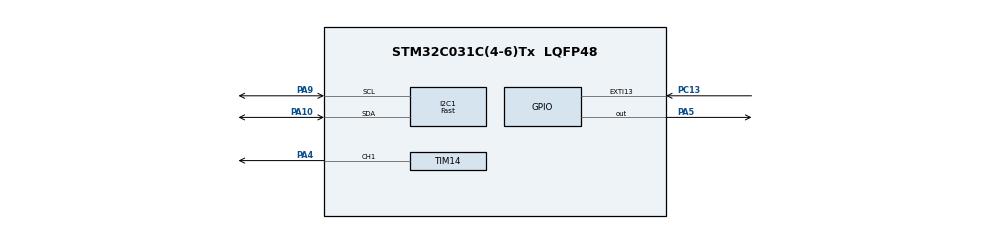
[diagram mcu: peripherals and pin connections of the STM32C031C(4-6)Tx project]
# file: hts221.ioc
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Dma.I2C1_RX.1.Direction=DMA_PERIPH_TO_MEMORY
Dma.I2C1_RX.1.EventEnable=DISABLE
Dma.I2C1_RX.1.Instance=DMA1_Channel2
Dma.I2C1_RX.1.MemDataAlignment=DMA_MDATAALIGN_BYTE
Dma.I2C1_RX.1.MemInc=DMA_MINC_ENABLE
Dma.I2C1_RX.1.Mode=DMA_NORMAL
Dma.I2C1_RX.1.PeriphDataAlignment=DMA_PDATAALIGN_BYTE
Dma.I2C1_RX.1.PeriphInc=DMA_PINC_DISABLE
Dma.I2C1_RX.1.Polarity=HAL_DMAMUX_REQ_GEN_RISING
Dma.I2C1_RX.1.Priority=DMA_PRIORITY_LOW
Dma.I2C1_RX.1.RequestNumber=1
Dma.I2C1_RX.1.SignalID=NONE
Dma.I2C1_RX.1.SyncEnable=DISABLE
Dma.I2C1_RX.1.SyncPolarity=HAL_DMAMUX_SYNC_NO_EVENT
Dma.I2C1_RX.1.SyncRequestNumber=1
Dma.I2C1_RX.1.SyncSignalID=NONE
Dma.I2C1_TX.0.Direction=DMA_MEMORY_TO_PERIPH
Dma.I2C1_TX.0.EventEnable=DISABLE
Dma.I2C1_TX.0.Instance=DMA1_Channel1
Dma.I2C1_TX.0.MemDataAlignment=DMA_MDATAALIGN_BYTE
Dma.I2C1_TX.0.MemInc=DMA_MINC_ENABLE
Dma.I2C1_TX.0.Mode=DMA_NORMAL
Dma.I2C1_TX.0.PeriphDataAlignment=DMA_PDATAALIGN_BYTE
Dma.I2C1_TX.0.PeriphInc=DMA_PINC_DISABLE
Dma.I2C1_TX.0.Polarity=HAL_DMAMUX_REQ_GEN_RISING
Dma.I2C1_TX.0.Priority=DMA_PRIORITY_LOW
Dma.I2C1_TX.0.RequestNumber=1
Dma.I2C1_TX.0.SignalID=NONE
Dma.I2C1_TX.0.SyncEnable=DISABLE
Dma.I2C1_TX.0.SyncPolarity=HAL_DMAMUX_SYNC_NO_EVENT
Dma.I2C1_TX.0.SyncRequestNumber=1
Dma.I2C1_TX.0.SyncSignalID=NONE
Dma.Request0=I2C1_TX
Dma.Request1=I2C1_RX
I2C1.CustomTiming=Disabled
I2C1.I2C_Fall_Time=0
I2C1.I2C_Rise_Time=0
I2C1.I2C_Speed_Mode=I2C_Fast
I2C1.Timing=0x2010091A
Mcu.Family=STM32C0
Mcu.Name=STM32C031C(4-6)Tx
Mcu.Package=LQFP48
NUCLEO-C031C6.BUTTON=1
NUCLEO-C031C6.Bsp_Common_DEMO=true
NUCLEO-C031C6.LD4=true
NUCLEO-C031C6.VCP=true
NVIC.DMA1_Channel1_IRQn=true\:0\:0\:false\:false\:true\:false\:true\:true
NVIC.DMA1_Channel2_3_IRQn=true\:0\:0\:false\:false\:true\:false\:true\:true
NVIC.EXTI4_15_IRQn=true\:0\:0\:false\:false\:true\:true\:true\:true
NVIC.I2C1_IRQn=true\:0\:0\:false\:false\:true\:true\:true\:true
NVIC.TIM14_IRQn=true\:0\:0\:false\:false\:true\:true\:true\:true
PA10.GPIO_Pu=GPIO_PULLUP
PA10.GPIO_Speed=GPIO_SPEED_FREQ_VERY_HIGH
PA10.Mode=I2C
PA10.Signal=I2C1_SDA
PA13.GPIO_Label=DEBUG_SWDIO
PA13.Signal=DEBUG_SWDIO
PA14-BOOT0.GPIO_Label=DEBUG_SWCLK
PA14-BOOT0.Signal=DEBUG_SWCLK
PA2.Signal=USART2_TX
PA3.Signal=USART2_RX
PA4.Signal=S_TIM14_CH1
PA5.Signal=GPIO_Output
PA9.GPIO_Pu=GPIO_PULLUP
PA9.GPIO_Speed=GPIO_SPEED_FREQ_VERY_HIGH
PA9.Mode=I2C
PA9.Signal=I2C1_SCL
PC13.Signal=GPXTI13
PC14-OSCX_IN\ (PC14).GPIO_Label=RCC_OSCX_IN
PC14-OSCX_IN\ (PC14).Mode=LSE-External-Oscillator
PC14-OSCX_IN\ (PC14).Signal=RCC_OSCX_IN
PC15-OSCX_OUT\ (PC15).GPIO_Label=RCC_OSCX_OUT
PC15-OSCX_OUT\ (PC15).Mode=LSE-External-Oscillator
PC15-OSCX_OUT\ (PC15).Signal=RCC_OSCX_OUT
PF0-OSC_IN\ (PF0).GPIO_Label=RCC_OSC_IN
PF0-OSC_IN\ (PF0).Mode=HSE-External-Oscillator
PF0-OSC_IN\ (PF0).Signal=RCC_OSC_IN
PF1-OSC_OUT\ (PF1).GPIO_Label=RCC_OSC_OUT
PF1-OSC_OUT\ (PF1).Mode=HSE-External-Oscillator
PF1-OSC_OUT\ (PF1).Signal=RCC_OSC_OUT
ProjectManager.HeapSize=0x200
ProjectManager.StackSize=0x400
ProjectManager.TargetToolchain=STM32CubeIDE
RCC.ADCFreq_Value=48000000
RCC.AHBFreq_Value=48000000
RCC.CortexFreq_Value=48000000
RCC.EXTERNAL_CLOCK_VALUE=12288000
RCC.HCLKFreq_Value=48000000
RCC.HSE_VALUE=48000000
RCC.HSISYSCLKDivider=RCC_HSI_DIV1
RCC.HSI_VALUE=48000000
RCC.SYSCLKFreq_VALUE=48000000
SH.S_TIM14_CH1.0=TIM14_CH1,PWM Generation1 CH1
TIM14.Channel=TIM_CHANNEL_1
TIM14.Period=10000
TIM14.Prescaler=4799
VP_NUCLEO-C031C6_VS_BSP_COMMON.Mode=COMMON
VP_TIM14_VS_ClockSourceINT.Mode=Enable_Timer
board=NUCLEO-C031C6

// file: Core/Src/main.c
/* USER CODE BEGIN Header */
/**
  ******************************************************************************
  * @file           : main.c
  * @brief          : Main program body
  ******************************************************************************
  * @attention
  *
  * Copyright (c) 2024 STMicroelectronics.
  * All rights reserved.
  *
  * This software is licensed under terms that can be found in the LICENSE file
  * in the root directory of this software component.
  * If no LICENSE file comes with this software, it is provided AS-IS.
  *
  ******************************************************************************
  */
/* USER CODE END Header */
#include "main.h"

COM_InitTypeDef BspCOMInit;
__IO uint32_t BspButtonState = BUTTON_RELEASED;

I2C_HandleTypeDef hi2c1;
DMA_HandleTypeDef hdma_i2c1_tx;
DMA_HandleTypeDef hdma_i2c1_rx;

TIM_HandleTypeDef htim14;

void SystemClock_Config(void);
static void MX_GPIO_Init(void);
static void MX_DMA_Init(void);
static void MX_I2C1_Init(void);
static void MX_TIM14_Init(void);

int main(void)
{

  /* MCU Configuration--------------------------------------------------------*/

  /* Reset of all peripherals, Initializes the Flash interface and the Systick. */
  HAL_Init();

  /* Configure the system clock */
  SystemClock_Config();

  /* Initialize all configured peripherals */
  MX_GPIO_Init();
  MX_DMA_Init();
  MX_I2C1_Init();
  MX_TIM14_Init();

  /* Initialize leds */
  BSP_LED_Init(LED_GREEN);

  /* Initialize USER push-button, will be used to trigger an interrupt each time it's pressed.*/
  BSP_PB_Init(BUTTON_USER, BUTTON_MODE_EXTI);

  /* Initialize COM1 port (115200, 8 bits (7-bit data + 1 stop bit), no parity */
  BspCOMInit.BaudRate   = 115200;
  BspCOMInit.WordLength = COM_WORDLENGTH_8B;
  BspCOMInit.StopBits   = COM_STOPBITS_1;
  BspCOMInit.Parity     = COM_PARITY_NONE;
  BspCOMInit.HwFlowCtl  = COM_HWCONTROL_NONE;
  if (BSP_COM_Init(COM1, &BspCOMInit) != BSP_ERROR_NONE)
  {
    Error_Handler();
  }

  /* USER CODE BEGIN BSP */

  /* -- Sample board code to send message over COM1 port ---- */
  printf("Welcome to STM32 world !\n\r");

  /* -- Sample board code to switch on leds ---- */
  BSP_LED_On(LED_GREEN);

  /* USER CODE END BSP */

  /* Infinite loop */
  while (1)
  {

  }
}

void SystemClock_Config(void)
{
  RCC_OscInitTypeDef RCC_OscInitStruct = {0};
  RCC_ClkInitTypeDef RCC_ClkInitStruct = {0};

  /** Initializes the RCC Oscillators according to the specified parameters
  * in the RCC_OscInitTypeDef structure.
  */
  RCC_OscInitStruct.OscillatorType = RCC_OSCILLATORTYPE_HSI;
  RCC_OscInitStruct.HSIState = RCC_HSI_ON;
  RCC_OscInitStruct.HSIDiv = RCC_HSI_DIV1;
  RCC_OscInitStruct.HSICalibrationValue = RCC_HSICALIBRATION_DEFAULT;
  if (HAL_RCC_OscConfig(&RCC_OscInitStruct) != HAL_OK)
  {
    Error_Handler();
  }

  /** Initializes the CPU, AHB and APB buses clocks
  */
  RCC_ClkInitStruct.ClockType = RCC_CLOCKTYPE_HCLK|RCC_CLOCKTYPE_SYSCLK
                              |RCC_CLOCKTYPE_PCLK1;
  RCC_ClkInitStruct.SYSCLKSource = RCC_SYSCLKSOURCE_HSI;
  RCC_ClkInitStruct.SYSCLKDivider = RCC_SYSCLK_DIV1;
  RCC_ClkInitStruct.AHBCLKDivider = RCC_HCLK_DIV1;
  RCC_ClkInitStruct.APB1CLKDivider = RCC_APB1_DIV1;

  if (HAL_RCC_ClockConfig(&RCC_ClkInitStruct, FLASH_LATENCY_1) != HAL_OK)
  {
    Error_Handler();
  }
}

static void MX_I2C1_Init(void)
{

  hi2c1.Instance = I2C1;
  hi2c1.Init.Timing = 0x2010091A;
  hi2c1.Init.OwnAddress1 = 0;
  hi2c1.Init.AddressingMode = I2C_ADDRESSINGMODE_7BIT;
  hi2c1.Init.DualAddressMode = I2C_DUALADDRESS_DISABLE;
  hi2c1.Init.OwnAddress2 = 0;
  hi2c1.Init.OwnAddress2Masks = I2C_OA2_NOMASK;
  hi2c1.Init.GeneralCallMode = I2C_GENERALCALL_DISABLE;
  hi2c1.Init.NoStretchMode = I2C_NOSTRETCH_DISABLE;
  if (HAL_I2C_Init(&hi2c1) != HAL_OK)
  {
    Error_Handler();
  }

  /** Configure Analogue filter
  */
  if (HAL_I2CEx_ConfigAnalogFilter(&hi2c1, I2C_ANALOGFILTER_ENABLE) != HAL_OK)
  {
    Error_Handler();
  }

  /** Configure Digital filter
  */
  if (HAL_I2CEx_ConfigDigitalFilter(&hi2c1, 0) != HAL_OK)
  {
    Error_Handler();
  }

}

static void MX_TIM14_Init(void)
{

  TIM_OC_InitTypeDef sConfigOC = {0};

  htim14.Instance = TIM14;
  htim14.Init.Prescaler = 4799;
  htim14.Init.CounterMode = TIM_COUNTERMODE_UP;
  htim14.Init.Period = 10000;
  htim14.Init.ClockDivision = TIM_CLOCKDIVISION_DIV1;
  htim14.Init.AutoReloadPreload = TIM_AUTORELOAD_PRELOAD_DISABLE;
  if (HAL_TIM_Base_Init(&htim14) != HAL_OK)
  {
    Error_Handler();
  }
  if (HAL_TIM_PWM_Init(&htim14) != HAL_OK)
  {
    Error_Handler();
  }
  sConfigOC.OCMode = TIM_OCMODE_PWM1;
  sConfigOC.Pulse = 0;
  sConfigOC.OCPolarity = TIM_OCPOLARITY_HIGH;
  sConfigOC.OCFastMode = TIM_OCFAST_DISABLE;
  if (HAL_TIM_PWM_ConfigChannel(&htim14, &sConfigOC, TIM_CHANNEL_1) != HAL_OK)
  {
    Error_Handler();
  }
  HAL_TIM_MspPostInit(&htim14);

}

static void MX_DMA_Init(void)
{

  /* DMA controller clock enable */
  __HAL_RCC_DMA1_CLK_ENABLE();

  /* DMA interrupt init */
  /* DMA1_Channel1_IRQn interrupt configuration */
  HAL_NVIC_SetPriority(DMA1_Channel1_IRQn, 0, 0);
  HAL_NVIC_EnableIRQ(DMA1_Channel1_IRQn);
  /* DMA1_Channel2_3_IRQn interrupt configuration */
  HAL_NVIC_SetPriority(DMA1_Channel2_3_IRQn, 0, 0);
  HAL_NVIC_EnableIRQ(DMA1_Channel2_3_IRQn);

}

static void MX_GPIO_Init(void)
{

  /* GPIO Ports Clock Enable */
  __HAL_RCC_GPIOC_CLK_ENABLE();
  __HAL_RCC_GPIOF_CLK_ENABLE();
  __HAL_RCC_GPIOA_CLK_ENABLE();

}

/**
  * @brief  BSP Push Button callback
  * @param  Button Specifies the pressed button
  * @retval None
  */
void BSP_PB_Callback(Button_TypeDef Button)
{
  if (Button == BUTTON_USER)
  {
    BspButtonState = BUTTON_PRESSED;
  }
}

void Error_Handler(void)
{
  __disable_irq();
  while (1)
  {
  }
}
